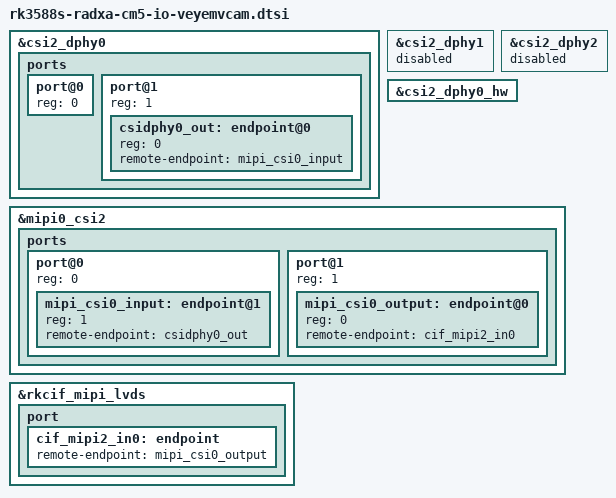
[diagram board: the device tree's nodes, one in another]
// SPDX-License-Identifier: (GPL-2.0+ OR MIT)
/*
 * Copyright (c) 2022 www.veye.cc
 *
 */

&csi2_dphy0 {
	status = "okay";
	ports {
		#address-cells = <1>;
		#size-cells = <0>;
		port@0 {
			reg = <0>;
			#address-cells = <1>;
			#size-cells = <0>;
		};
		port@1 {
			reg = <1>;
			#address-cells = <1>;
			#size-cells = <0>;

			csidphy0_out: endpoint@0 {
				reg = <0>;
				remote-endpoint = <&mipi_csi0_input>;
			};
		};
	};
};

&csi2_dphy1 {
	status = "disabled";
};

&csi2_dphy2 {
	status = "disabled";
};

&csi2_dphy0_hw {
	status = "okay";
};


&mipi0_csi2 { //Modified to mipi0_csi2
	status = "okay";

	ports {
		#address-cells = <1>;
		#size-cells = <0>;

		port@0 {
			reg = <0>;
			#address-cells = <1>;
			#size-cells = <0>;

			mipi_csi0_input: endpoint@1 {
				reg = <1>;
				remote-endpoint = <&csidphy0_out>;
			};
		};

		port@1 {
			reg = <1>;
			#address-cells = <1>;
			#size-cells = <0>;

			mipi_csi0_output: endpoint@0 {
				reg = <0>;
				remote-endpoint = <&cif_mipi2_in0>;
			};
		};
	};
};

&rkcif_mipi_lvds {
	status = "okay";

	port {
		cif_mipi2_in0: endpoint {
			remote-endpoint = <&mipi_csi0_output>; // Modified enpoint renamed
		};
	};
};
